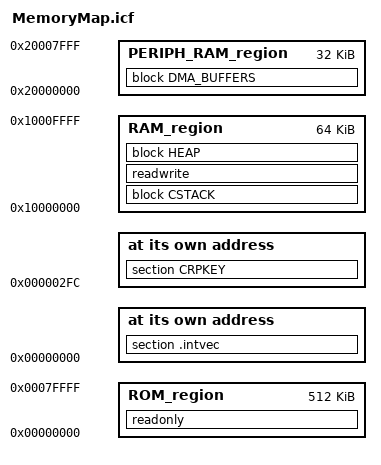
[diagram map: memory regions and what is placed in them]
/*###ICF### Section handled by ICF editor, don't touch! ****/
/*-Editor annotation file-*/
/* IcfEditorFile="$TOOLKIT_DIR$\config\ide\IcfEditor\cortex_v1_0.xml" */
/*-Specials-*/

define symbol __ICFEDIT_intvec_start__ = 0x00000000;

/*-Memory Regions-*/
define symbol __ICFEDIT_region_ROM_start__    = 0x00000000;
define symbol __ICFEDIT_region_ROM_end__      = 0x0007FFFF;
define symbol __ICFEDIT_region_RAM_start__    = 0x10000000;
define symbol __ICFEDIT_region_RAM_end__      = 0x1000FFFF;

/*-Sizes-*/
define symbol __ICFEDIT_size_cstack__ = 0x2000;
define symbol __ICFEDIT_size_heap__   = 0x2000;
define symbol __ICFEDIT_size_dma__    = 0x1000;
/**** End of ICF editor section. ###ICF###*/

define memory mem with size = 4G;
define region ROM_region     = mem:[from __ICFEDIT_region_ROM_start__      to __ICFEDIT_region_ROM_end__];
define region RAM_region     = mem:[from __ICFEDIT_region_RAM_start__      to __ICFEDIT_region_RAM_end__];

define symbol _PERIPH_RAM_start__  = 0x20000000;
define symbol _PERIPH_RAM_end__    = 0x20007FFF;
define region PERIPH_RAM_region = mem:[from _PERIPH_RAM_start__ to _PERIPH_RAM_end__];

define block CSTACK      with alignment = 8, size = __ICFEDIT_size_cstack__     { };
define block HEAP        with alignment = 8, size = __ICFEDIT_size_heap__       { };
define block DMA_BUFFERS with alignment = 8, size = __ICFEDIT_size_dma__        { section .dma_buffers };

initialize by copy with packing = zeros { section .data };

place at address mem:__ICFEDIT_intvec_start__ { section .intvec };
place at address mem:0x2FC      { section CRPKEY };
place in ROM_region             { readonly };
place in RAM_region             { block CSTACK, readwrite, block HEAP }; 
place in PERIPH_RAM_region      { block DMA_BUFFERS };

